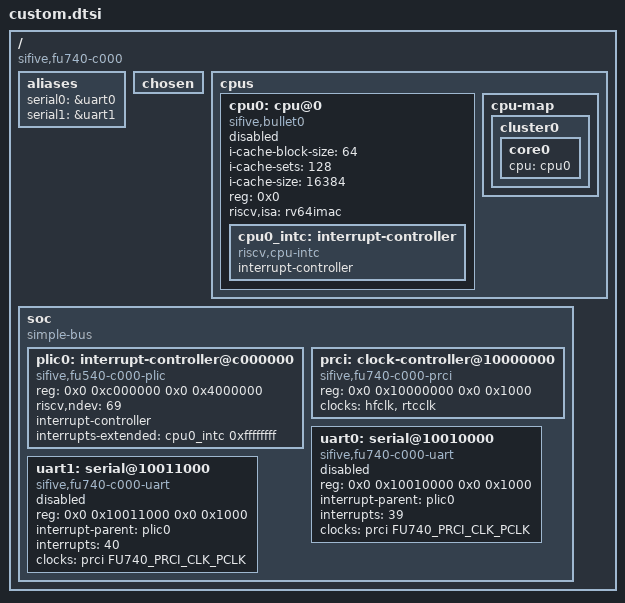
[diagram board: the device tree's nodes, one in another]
// SPDX-License-Identifier: (GPL-2.0 OR MIT)
/* Copyright (c) 2020 SiFive, Inc */

/dts-v1/;

#include <dt-bindings/clock/sifive-fu740-prci.h>
/ {
	#address-cells = <2>;
	#size-cells = <2>;
	compatible = "sifive,fu740-c000", "sifive,fu740";

	aliases {
		serial0 = &uart0;
		serial1 = &uart1;
	};

	chosen {
	};

	cpus {
		#address-cells = <1>;
		#size-cells = <0>;
		cpu0: cpu@0 {
			compatible = "sifive,bullet0", "riscv";
			device_type = "cpu";
			i-cache-block-size = <64>;
			i-cache-sets = <128>;
			i-cache-size = <16384>;
			reg = <0x0>;
			riscv,isa = "rv64imac";
			status = "disabled";
			cpu0_intc: interrupt-controller {
				#interrupt-cells = <1>;
				compatible = "riscv,cpu-intc";
				interrupt-controller;
			};
		};

		cpu-map {
			cluster0 {
				core0 {
					cpu = <&cpu0>;
				};
			};
		};
	};
	soc {
		#address-cells = <2>;
		#size-cells = <2>;
		compatible = "simple-bus";
		ranges;
		plic0: interrupt-controller@c000000 {
			#interrupt-cells = <1>;
			#address-cells = <0>;
			compatible = "sifive,fu540-c000-plic", "sifive,plic-1.0.0";
			reg = <0x0 0xc000000 0x0 0x4000000>;
			riscv,ndev = <69>;
			interrupt-controller;
			interrupts-extended =
				<&cpu0_intc 0xffffffff>;
		};
		prci: clock-controller@10000000 {
			compatible = "sifive,fu740-c000-prci";
			reg = <0x0 0x10000000 0x0 0x1000>;
			clocks = <&hfclk>, <&rtcclk>;
			#clock-cells = <1>;
			#reset-cells = <1>;
		};
		uart0: serial@10010000 {
			compatible = "sifive,fu740-c000-uart", "sifive,uart0";
			reg = <0x0 0x10010000 0x0 0x1000>;
			interrupt-parent = <&plic0>;
			interrupts = <39>;
			clocks = <&prci FU740_PRCI_CLK_PCLK>;
			status = "disabled";
		};
		uart1: serial@10011000 {
			compatible = "sifive,fu740-c000-uart", "sifive,uart0";
			reg = <0x0 0x10011000 0x0 0x1000>;
			interrupt-parent = <&plic0>;
			interrupts = <40>;
			clocks = <&prci FU740_PRCI_CLK_PCLK>;
			status = "disabled";
		};
	};
};
